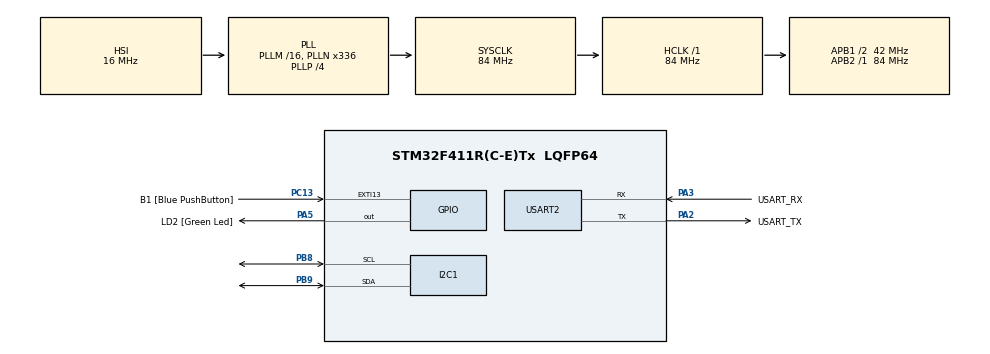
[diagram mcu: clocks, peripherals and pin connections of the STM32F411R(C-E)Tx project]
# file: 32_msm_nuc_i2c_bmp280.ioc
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Mcu.Family=STM32F4
PC15-OSC32_OUT.Mode=LSE-External-Oscillator
RCC.CortexFreq_Value=84000000
PC13-ANTI_TAMP.GPIO_Label=B1 [Blue PushButton]
PA14.GPIO_Label=TCK
PH1\ -\ OSC_OUT.Mode=HSE-External-Clock-Source
RCC.APB1CLKDivider=RCC_HCLK_DIV2
PC14-OSC32_IN.Signal=RCC_OSC32_IN
RCC.SYSCLKSource=RCC_SYSCLKSOURCE_PLLCLK
ProjectManager.StackSize=0x400
PA13.Signal=SYS_JTMS-SWDIO
PA3.Mode=Asynchronous
PH0\ -\ OSC_IN.Mode=HSE-External-Clock-Source
PH0\ -\ OSC_IN.Signal=RCC_OSC_IN
ProjectManager.TargetToolchain=STM32CubeIDE
RCC.HCLKFreq_Value=84000000
PB9.Mode=I2C
RCC.APB2TimFreq_Value=84000000
PC15-OSC32_OUT.Signal=RCC_OSC32_OUT
RCC.AHBFreq_Value=84000000
PA5.Signal=GPIO_Output
RCC.HSE_VALUE=8000000
PH1\ -\ OSC_OUT.Signal=RCC_OSC_OUT
board=NUCLEO-F411RE
PC13-ANTI_TAMP.Signal=GPXTI13
RCC.VCOOutputFreq_Value=336000000
RCC.APB2Freq_Value=84000000
PC14-OSC32_IN.Mode=LSE-External-Oscillator
PA14.Mode=Serial_Wire
PA13.Mode=Serial_Wire
Mcu.Name=STM32F411R(C-E)Tx
PA2.Signal=USART2_TX
PA13.GPIO_Label=TMS
RCC.FLatency-AdvancedSettings=FLASH_LATENCY_2
RCC.48MHZClocksFreq_Value=84000000
PB3.Signal=SYS_JTDO-SWO
RCC.SYSCLKFreq_VALUE=84000000
Mcu.Package=LQFP64
PB9.Signal=I2C1_SDA
PA5.GPIO_Label=LD2 [Green Led]
USART2.VirtualMode=VM_ASYNC
PC13-ANTI_TAMP.GPIO_ModeDefaultEXTI=GPIO_MODE_IT_FALLING
PA2.GPIO_Label=USART_TX
PA14.Signal=SYS_JTCK-SWCLK
ProjectManager.HeapSize=0x200
RCC.HSI_VALUE=16000000
RCC.PLLP=RCC_PLLP_DIV4
NVIC.PriorityGroup=NVIC_PRIORITYGROUP_0
PB8.Mode=I2C
RCC.PLLN=336
RCC.APB1TimFreq_Value=84000000
PA2.Mode=Asynchronous
PB8.Signal=I2C1_SCL
RCC.APB1Freq_Value=42000000
PA3.GPIO_Label=USART_RX
PA3.Signal=USART2_RX
PB3.GPIO_Label=SWO

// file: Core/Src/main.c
/* USER CODE BEGIN Header */
/**
  ******************************************************************************
  * @file           : main.c
  * @brief          : Main program body
  ******************************************************************************
  * @attention
  *
  * <h2><center>&copy; Copyright (c) 2021 STMicroelectronics.
  * All rights reserved.</center></h2>
  *
  * This software component is licensed by ST under BSD 3-Clause license,
  * the "License"; You may not use this file except in compliance with the
  * License. You may obtain a copy of the License at:
  *                        opensource.org/licenses/BSD-3-Clause
  *
  ******************************************************************************
  */
/* USER CODE END Header */
#include "main.h"
#include "i2c.h"
#include "usart.h"
#include "gpio.h"

/* USER CODE BEGIN Includes */
#include "bmp280.h"
/* USER CODE END Includes */

/* USER CODE BEGIN PD */
#define BMP280_ADDRESS 0x76
/* USER CODE END PD */

/* USER CODE BEGIN PV */
BMP280_t Bmp280;
/* USER CODE END PV */

void SystemClock_Config(void);

int main(void)
{

  /* MCU Configuration--------------------------------------------------------*/

  /* Reset of all peripherals, Initializes the Flash interface and the Systick. */
  HAL_Init();

  /* Configure the system clock */
  SystemClock_Config();

  /* Initialize all configured peripherals */
  MX_GPIO_Init();
  MX_USART2_UART_Init();
  MX_I2C1_Init();
  /* USER CODE BEGIN 2 */
  BMP280_Init(&Bmp280, &hi2c1, BMP280_ADDRESS);
  float Temp, Pressure;

  /* USER CODE END 2 */

  /* Infinite loop */
  /* USER CODE BEGIN WHILE */
  while (1)
  {
	  BMP280_ReadPressureAndTemperature(&Bmp280, &Pressure, &Temp);
	  HAL_Delay(100);

    /* USER CODE END WHILE */

  }
}

void SystemClock_Config(void)
{
  RCC_OscInitTypeDef RCC_OscInitStruct = {0};
  RCC_ClkInitTypeDef RCC_ClkInitStruct = {0};

  /** Configure the main internal regulator output voltage
  */
  __HAL_RCC_PWR_CLK_ENABLE();
  __HAL_PWR_VOLTAGESCALING_CONFIG(PWR_REGULATOR_VOLTAGE_SCALE1);
  /** Initializes the RCC Oscillators according to the specified parameters
  * in the RCC_OscInitTypeDef structure.
  */
  RCC_OscInitStruct.OscillatorType = RCC_OSCILLATORTYPE_HSI;
  RCC_OscInitStruct.HSIState = RCC_HSI_ON;
  RCC_OscInitStruct.HSICalibrationValue = RCC_HSICALIBRATION_DEFAULT;
  RCC_OscInitStruct.PLL.PLLState = RCC_PLL_ON;
  RCC_OscInitStruct.PLL.PLLSource = RCC_PLLSOURCE_HSI;
  RCC_OscInitStruct.PLL.PLLM = 16;
  RCC_OscInitStruct.PLL.PLLN = 336;
  RCC_OscInitStruct.PLL.PLLP = RCC_PLLP_DIV4;
  RCC_OscInitStruct.PLL.PLLQ = 4;
  if (HAL_RCC_OscConfig(&RCC_OscInitStruct) != HAL_OK)
  {
    Error_Handler();
  }
  /** Initializes the CPU, AHB and APB buses clocks
  */
  RCC_ClkInitStruct.ClockType = RCC_CLOCKTYPE_HCLK|RCC_CLOCKTYPE_SYSCLK
                              |RCC_CLOCKTYPE_PCLK1|RCC_CLOCKTYPE_PCLK2;
  RCC_ClkInitStruct.SYSCLKSource = RCC_SYSCLKSOURCE_PLLCLK;
  RCC_ClkInitStruct.AHBCLKDivider = RCC_SYSCLK_DIV1;
  RCC_ClkInitStruct.APB1CLKDivider = RCC_HCLK_DIV2;
  RCC_ClkInitStruct.APB2CLKDivider = RCC_HCLK_DIV1;

  if (HAL_RCC_ClockConfig(&RCC_ClkInitStruct, FLASH_LATENCY_2) != HAL_OK)
  {
    Error_Handler();
  }
}

void Error_Handler(void)
{
  __disable_irq();
  while (1)
  {
  }
}

/************************ (C) COPYRIGHT STMicroelectronics *****END OF FILE****/
